# npcx9m6f register map
Registers are 8-bit, read-write, no defined reset value unless marked. A register's access mark holds for its fields unless they carry their own. Offsets are from the block's base; [hi:lo] are bit positions; {n}, {i} and the like mark numbered series; 'fields as' and 'values as' point back to an identical list.

## DBG — Debug Support
Base 0x400C3000
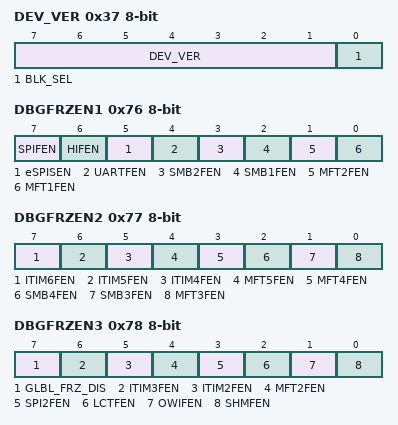
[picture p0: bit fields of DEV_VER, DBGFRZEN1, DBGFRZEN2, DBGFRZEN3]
0x37 DEV_VER
  [7:1] DEV_VER, [0] BLK_SEL
0x74 DBG_CTL
  [2] CLKLP_DBGCOPN
0x76 DBGFRZEN1
  [7] SPIFEN, [6] HIFEN, [5] eSPISEN, [4] UARTFEN, [3] SMB2FEN, [2] SMB1FEN, [1] MFT2FEN, [0] MFT1FEN
0x77 DBGFRZEN2
  [7] ITIM6FEN, [6] ITIM5FEN, [5] ITIM4FEN, [4] MFT5FEN, [3] MFT4FEN, [2] SMB4FEN, [1] SMB3FEN, [0] MFT3FEN
0x78 DBGFRZEN3
  [7] GLBL_FRZ_DIS, [6] ITIM3FEN, [5] ITIM2FEN, [4] MFT2FEN, [3] SPI2FEN, [2] LCTFEN, [1] OWIFEN, [0] SHMFEN
0x79 DBGFRZEN4
  [1] ASIFFEN, [1] SMB5FEN, [1] SMB6FEN, [0] MBIFEN

## SYSTEM_GLUE — System Glue Registers
Base 0x400A5000
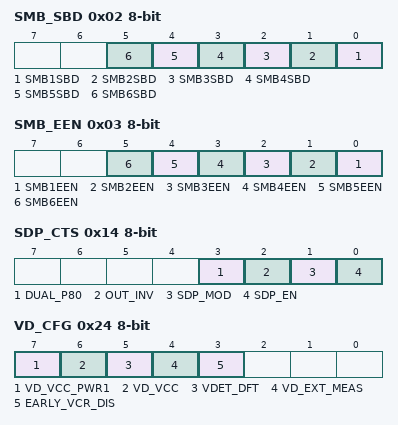
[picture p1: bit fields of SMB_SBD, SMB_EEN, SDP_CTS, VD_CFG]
0x02 SMB_SBD
  [n-1] SMB{n}SBD (n=1..6)
0x03 SMB_EEN
  [n-1] SMB{n}EEN (n=1..6)
0x10 SDPD0
0x12 SDPD1
0x14 SDP_CTS
  [3] DUAL_P80, [2] OUT_INV, [1] SDP_MOD, [0] SDP_EN
0x16 KBRD_DLY
  [5:0] DLY_VAL
0x1A GLUE_VER
0x21 SMB_SEL
  [0] SMB0_SL
0x24 VD_CFG
  [7] VD_VCC_PWR1, [6] VD_VCC, [5] VDET_DFT, [4] VD_EXT_MEAS, [3] EARLY_VCR_DIS
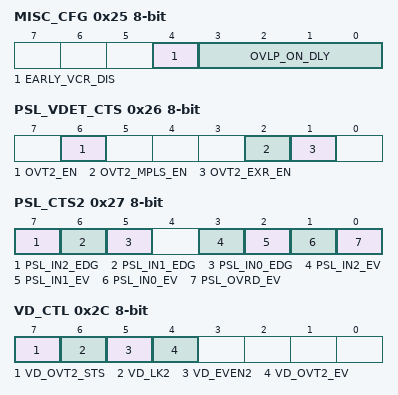
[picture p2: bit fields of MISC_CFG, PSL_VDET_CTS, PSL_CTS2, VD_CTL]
0x25 MISC_CFG
  [4] EARLY_VCR_DIS, [3:0] OVLP_ON_DLY
0x26 PSL_VDET_CTS
  [6] OVT2_EN, [2] OVT2_MPLS_EN, [1] OVT2_EXR_EN
0x27 PSL_CTS2
  [7] PSL_IN2_EDG, [6] PSL_IN1_EDG, [5] PSL_IN0_EDG, [3] PSL_IN2_EV, [2] PSL_IN1_EV, [1] PSL_IN0_EV, [0] PSL_OVRD_EV
0x2A VD_THD2
0x2B VD_THU2
0x2C VD_CTL
  [7] VD_OVT2_STS, [6] VD_LK2, [5] VD_EVEN2, [4] VD_OVT2_EV
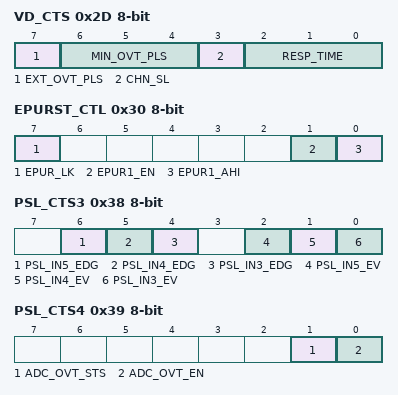
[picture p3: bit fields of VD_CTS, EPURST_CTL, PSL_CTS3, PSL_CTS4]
0x2D VD_CTS
  [7] EXT_OVT_PLS, [6:4] MIN_OVT_PLS, [3] CHN_SL, [2:0] RESP_TIME
0x30 EPURST_CTL
  [7] EPUR_LK, [1] EPUR1_EN, [0] EPUR1_AHI
0x31 EPURST_DBC
  [4:0] EPUR_DBC
0x38 PSL_CTS3
  [6] PSL_IN5_EDG, [5] PSL_IN4_EDG, [4] PSL_IN3_EDG, [2] PSL_IN5_EV, [1] PSL_IN4_EV, [0] PSL_IN3_EV
0x39 PSL_CTS4
  [1] ADC_OVT_STS, [0] ADC_OVT_EN

## MDC — Miscellaneous Device Control Module
Base 0x4000C000
0x05 BSC0
0x07 BSC1
0x0A HEAD_BASEL 16-bit
0x0C HEAD_BASEH 16-bit
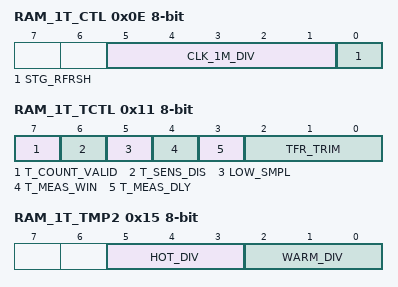
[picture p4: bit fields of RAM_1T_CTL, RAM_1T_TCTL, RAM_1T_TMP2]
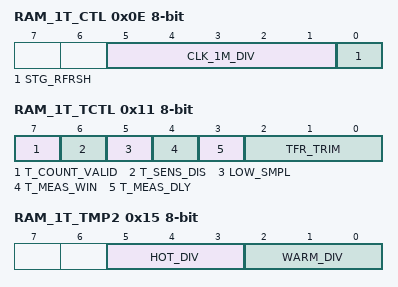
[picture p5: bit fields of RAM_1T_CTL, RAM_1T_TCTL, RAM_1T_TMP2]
0x0E RAM_1T_CTL
  [5:1] CLK_1M_DIV, [0] STG_RFRSH
0x0F MDC_VERSION
0x10 RAM_1T_CLK_COUNT 16-bit
  [11:0] T_CLK_COUNT
0x11 RAM_1T_TCTL
  [7] T_COUNT_VALID, [6] T_SENS_DIS, [5] LOW_SMPL, [4] T_MEAS_WIN, [3] T_MEAS_DLY, [2:0] TFR_TRIM
0x12 RAM_1T_WH_THR
0x13 RAM_1T_CW_THR
0x14 RAM_1T_TMP1
  [2:0] COLD_DIV
0x15 RAM_1T_TMP2
  [5:3] HOT_DIV, [2:0] WARM_DIV

## MDC — Micellaneous Device Control Module
Base 0x4000C000
0x02 MRAM_LOCK
0x04 MRAM_VALID
0x05 BSC0
0x06 MRAM_UNLOCK
0x07 BSC1
0x08 MRAM_LK_VIOL
0x0A HEAD_BASEL 16-bit
0x0C HEAD_BASEH 16-bit
0x0E RAM_1T_CTL
  [5:1] CLK_1M_DIV, [0] STG_RFRSH
0x0F MDC_VERSION
0x10 RAM_1T_CLK_COUNT 16-bit
  [11:0] T_CLK_COUNT
0x11 RAM_1T_TCTL
  fields as RAM_1T_TCTL
0x12 RAM_WH_THR
0x13 RAM_CW_THR
0x14 RAM_1T_TMP1
  [5:3] COLD_DIV
0x15 RAM_1T_TMP2
  [5:3] HOT_DIV, [2:0] WARM_DIV
0x16 MRAM_LOCK_EX
0x17 MRAM_LOCK_EX1
0x18 MRAM_LK_VIOL_EX
0x19 MRAM_LK_VIOL_EX1

## GDMA — GDMA Controller Module
Base 0x40011000
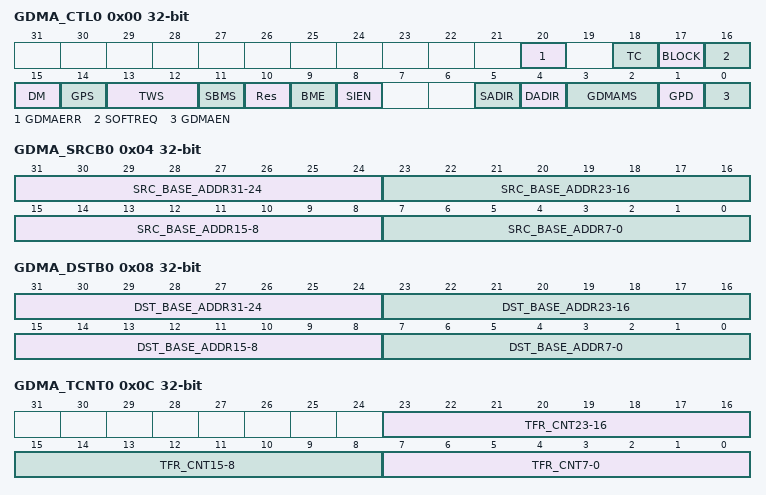
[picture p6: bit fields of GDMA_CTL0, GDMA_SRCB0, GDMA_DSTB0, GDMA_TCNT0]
0x00 GDMA_CTL0 32-bit
  [20] GDMAERR, [18] TC, [17] BLOCK, [16] SOFTREQ, [15] DM, [14] GPS, [13:12] TWS, [11] SBMS, [10] Res, [9] BME, [8] SIEN, [5] SADIR, [4] DADIR, [3:2] GDMAMS, [1] GPD, [0] GDMAEN
0x04 GDMA_SRCB0 32-bit
  [31:24] SRC_BASE_ADDR31-24, [23:16] SRC_BASE_ADDR23-16, [15:8] SRC_BASE_ADDR15-8, [7:0] SRC_BASE_ADDR7-0
0x08 GDMA_DSTB0 32-bit
  [31:24] DST_BASE_ADDR31-24, [23:16] DST_BASE_ADDR23-16, [15:8] DST_BASE_ADDR15-8, [7:0] DST_BASE_ADDR7-0
0x0C GDMA_TCNT0 32-bit
  [23:16] TFR_CNT23-16, [15:8] TFR_CNT15-8, [7:0] TFR_CNT7-0
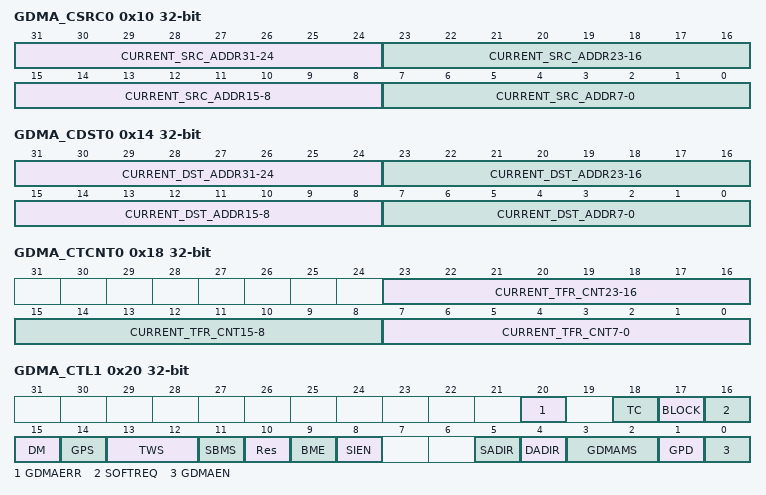
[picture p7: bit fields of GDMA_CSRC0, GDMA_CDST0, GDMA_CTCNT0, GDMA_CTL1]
0x10 GDMA_CSRC0 32-bit
  [31:24] CURRENT_SRC_ADDR31-24, [23:16] CURRENT_SRC_ADDR23-16, [15:8] CURRENT_SRC_ADDR15-8, [7:0] CURRENT_SRC_ADDR7-0
0x14 GDMA_CDST0 32-bit
  [31:24] CURRENT_DST_ADDR31-24, [23:16] CURRENT_DST_ADDR23-16, [15:8] CURRENT_DST_ADDR15-8, [7:0] CURRENT_DST_ADDR7-0
0x18 GDMA_CTCNT0 32-bit
  [23:16] CURRENT_TFR_CNT23-16, [15:8] CURRENT_TFR_CNT15-8, [7:0] CURRENT_TFR_CNT7-0
0x20 GDMA_CTL1 32-bit
  fields as GDMA_CTL0
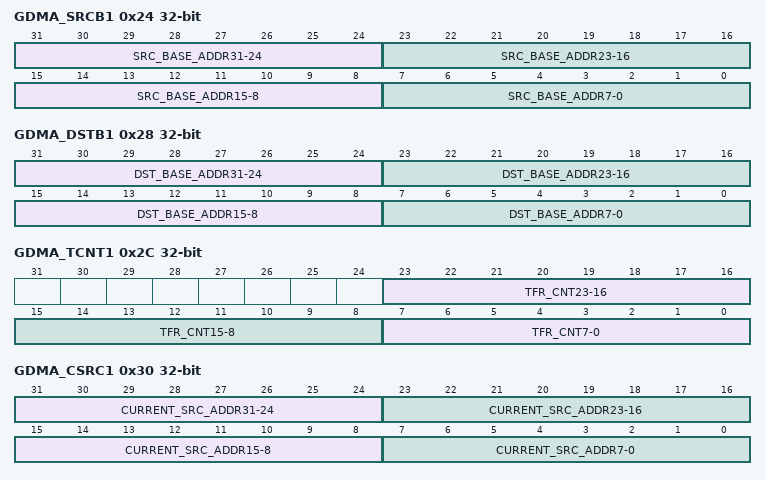
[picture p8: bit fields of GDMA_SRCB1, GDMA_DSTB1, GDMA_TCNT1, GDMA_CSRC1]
0x24 GDMA_SRCB1 32-bit
  fields as GDMA_SRCB0
0x28 GDMA_DSTB1 32-bit
  fields as GDMA_DSTB0
0x2C GDMA_TCNT1 32-bit
  [23:16] TFR_CNT23-16, [15:8] TFR_CNT15-8, [7:0] TFR_CNT7-0
0x30 GDMA_CSRC1 32-bit
  fields as GDMA_CSRC0
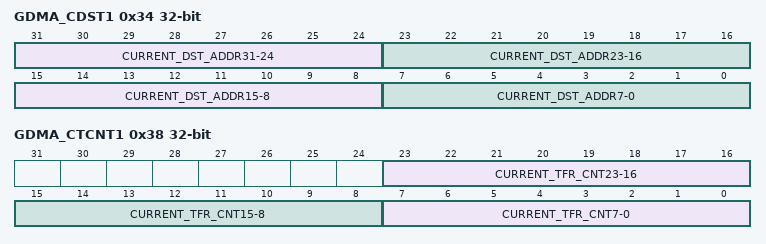
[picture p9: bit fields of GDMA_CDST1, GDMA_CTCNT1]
0x34 GDMA_CDST1 32-bit
  fields as GDMA_CDST0
0x38 GDMA_CTCNT1 32-bit
  fields as GDMA_CTCNT0
